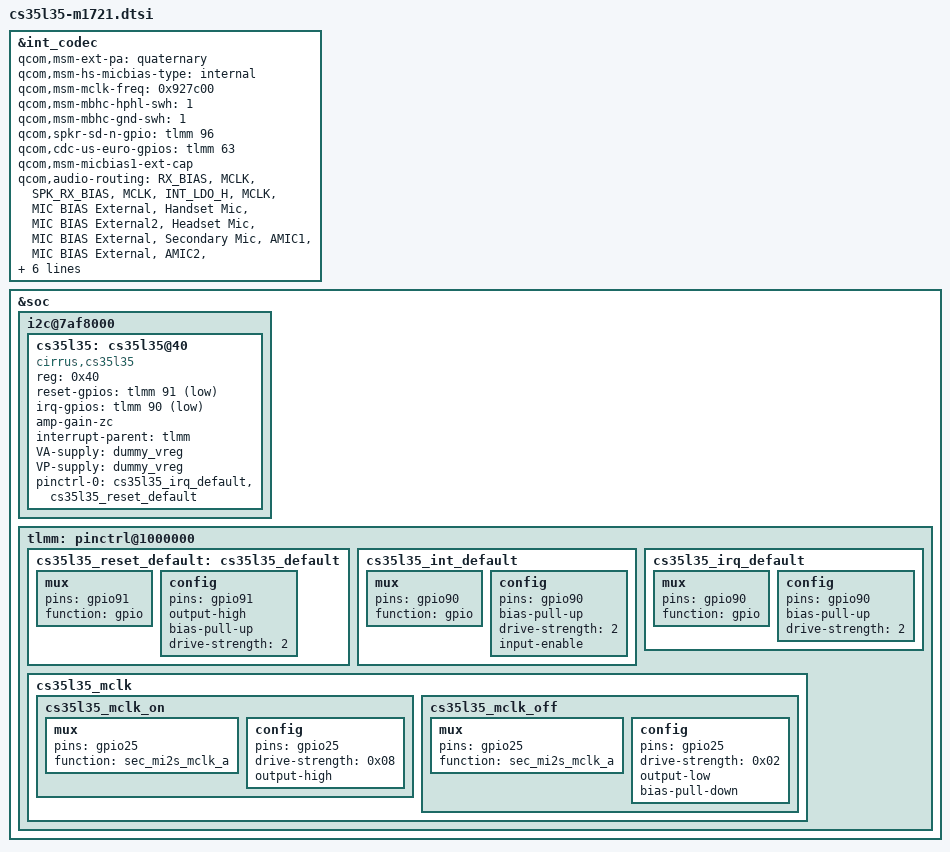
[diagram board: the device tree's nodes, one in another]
/*
 * Copyright (c) 2017, The Linux Foundation. All rights reserved.
 *
 * This program is free software; you can redistribute it and/or modify
 * it under the terms of the GNU General Public License version 2 and
 * only version 2 as published by the Free Software Foundation.
 *
 * This program is distributed in the hope that it will be useful,
 * but WITHOUT ANY WARRANTY; without even the implied warranty of
 * MERCHANTABILITY or FITNESS FOR A PARTICULAR PURPOSE.  See the
 * GNU General Public License for more details.
 */

/* cs35l35 codec */

&int_codec {
	status = "ok";
	/* already defined in msm8953-audio.dtsi */
	qcom,msm-ext-pa = "quaternary";
    qcom,msm-hs-micbias-type = "internal";
    qcom,msm-mclk-freq = <0x927c00>;
    qcom,msm-mbhc-hphl-swh = <1>;
    qcom,msm-mbhc-gnd-swh = <1>;
	qcom,spkr-sd-n-gpio = <&tlmm 96 0>;
    qcom,cdc-us-euro-gpios = <&tlmm 63 0>;
    qcom,msm-micbias1-ext-cap;
	qcom,audio-routing =
        "RX_BIAS", "MCLK",
        "SPK_RX_BIAS", "MCLK",
        "INT_LDO_H", "MCLK",
        "MIC BIAS External", "Handset Mic",
        "MIC BIAS External2", "Headset Mic",
        "MIC BIAS External", "Secondary Mic",
        "AMIC1", "MIC BIAS External",
        "AMIC2", "MIC BIAS External2",
        "AMIC3", "MIC BIAS External",
        "WSA_SPK OUT", "VDD_WSA_SWITCH",
        "SpkrMono WSA_IN", "WSA_SPK OUT";
    msm-vdd-wsa-switch-supply = <&pm8953_l5>;
    qcom,msm-vdd-wsa-switch-voltage = <0x1b7740>;
    qcom,msm-vdd-wsa-switch-current = <0x2710>;
	/delete-property/asoc-wsa-codec-names;
	/delete-property/asoc-wsa-codec-prefixes;
};

/* cs35l35 dts */

&soc {
    i2c@7af8000 {
        cs35l35: cs35l35@40 {
            compatible = "cirrus,cs35l35";
            reg = <0x40>;
            reset-gpios = <&tlmm 91 1>;
            irq-gpios = <&tlmm 90 1>;
            amp-gain-zc;
            interrupt-parent = <&tlmm>;

            VA-supply = <&dummy_vreg>;
            VP-supply = <&dummy_vreg>;
            pinctrl-names = "default";
            pinctrl-0 = <&cs35l35_irq_default &cs35l35_reset_default>;
        };
    };
};

/* cs35l35 pinctrl */
&soc {
	tlmm: pinctrl@1000000 {
                cs35l35_reset_default: cs35l35_default {

            mux {
                pins = "gpio91";
                function = "gpio";
            };

            config {
                pins = "gpio91";
                output-high;
                bias-pull-up;
                drive-strength = <2>; /* 2 mA */
            };
        };

        cs35l35_int_default: cs35l35_int_default {

            mux {
                pins = "gpio90";
                function = "gpio";
            };

            config {
                pins = "gpio90";
                bias-pull-up;
                drive-strength = <2>; /* 2 mA */
                input-enable;
            };
        };
		
		cs35l35_irq_default: cs35l35_irq_default {
			
			mux {
				pins = "gpio90";
				function = "gpio";
			};

			config {
				pins = "gpio90";
				bias-pull-up;
				drive-strength = <2>; /* 2 mA */
			};
		};
        
        cs35l35_mclk: cs35l35_mclk {

            cs35l35_mclk_on: cs35l35_mclk_on {
                linux,phandle = <0x175>;
                phandle = <0x175>;

                mux {
                    pins = "gpio25";
                    function = "sec_mi2s_mclk_a";
                };

                config {
                    pins = "gpio25";
                    drive-strength = <0x08>;
                    output-high;
                };
            };

            cs35l35_mclk_off: cs35l35_mclk_off {
                linux,phandle = <0x147>;
                phandle = <0x147>;

                mux {
                    pins = "gpio25";
                    function = "sec_mi2s_mclk_a";
                };

                config {
                    pins = "gpio25";
                    drive-strength = <0x02>;
                    output-low;
                    bias-pull-down;
                };
            };
        };
	};
};



/* cs35l35 pinctrl */
